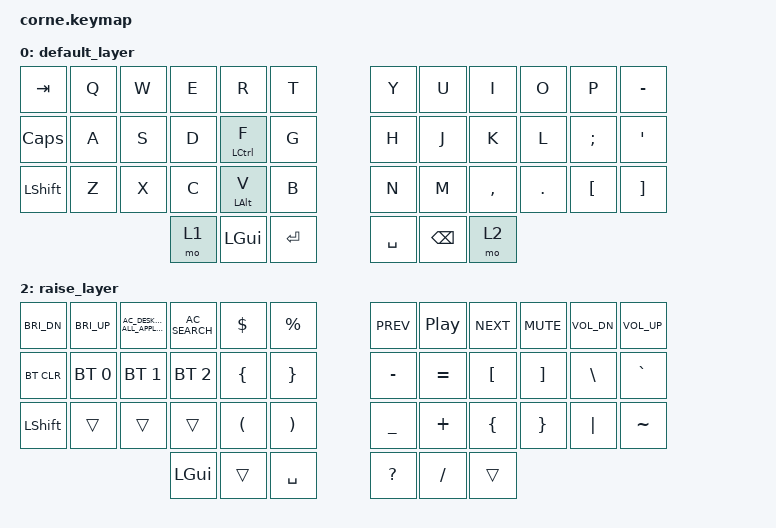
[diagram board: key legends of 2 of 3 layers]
/*
 * Copyright (c) 2020 The ZMK Contributors
 *
 * SPDX-License-Identifier: MIT
 */

#include <behaviors.dtsi>
#include <dt-bindings/zmk/keys.h>
#include <dt-bindings/zmk/bt.h>

&mt {
    flavor = "balanced";
    tapping-term-ms = <300>;
};

/ {
        keymap {
                compatible = "zmk,keymap";

                default_layer {
// -----------------------------------------------------------------------------------------
// |  TAB |  Q  |  W  |  E  |  R  |  T  |   |  Y  |  U   |  I  |  O  |  P  |  -   |
// | CAPS |  A  |  S  |  D  |F,CMD|  G  |   |  H  |  J   |  K  |  L  |  ;  |  '   |
// | SHFT |  Z  |  X  |  C  |V,ALT|  B  |   |  N  |  M   |  ,  |  .  |  [  |  ]   |
//                    | LWR | GUI | ENT |   | SPC | BKSP | RSE |
                        bindings = <
   &kp TAB   &kp Q &kp W &kp E &kp R &kp T        &kp Y &kp U  &kp I     &kp O   &kp P    &kp MINUS
   &kp CAPS &kp A &kp S &kp D &mt LCTRL F &kp G   &kp H &kp J  &kp K     &kp L   &kp SEMI &kp SQT
   &kp LSHFT &kp Z &kp X &kp C &mt LALT V &kp B        &kp N &kp M  &kp COMMA &kp DOT &kp LBKT  &kp RBKT
                  &mo 1 &kp LGUI &kp RET        &kp SPACE &kp BSPC &mo 2
                        >;
                };
                lower_layer {
// -----------------------------------------------------------------------------------------
// |  ESC |  !  |  @  |  #  |  $  |  %    |   |  1  |  2  |  3  |  +  |  -  |   =  |
// | BTPRV|  ^  |  &  |  *  |PG_UP| BTNXT |   |  4  |  5  |  6  |  *  |  UP |   :  |
// |      |  `  | END |HOME |PG_DN|SCRNSHT|   |  7  |  8  |  9  | LFT | DWN |  RGT |
//                    |     | GUI |       |   | ALT |  0  |     |
                        bindings = <
   &kp ESC  &kp EXCL &kp AT &kp NON_US_HASH &kp DLLR &kp PRCNT                         &kp N1   &kp N2   &kp N3  &kp KP_PLUS  &kp KP_MINUS &kp KP_EQUAL
   &bt BT_PRV &kp CARET &kp AMPS  &kp KP_MULTIPLY &bt &kp PG_UP &bt BT_NXT   &kp N4  &kp N5  &kp N6  &kp KP_MULTIPLY &kp UP &kp KP_DIVIDE
   &trans  &kp GRAVE  &kp END  &kp HOME  &kp PG_DN  &kp LS(LC(LG(N4)))     &kp N7  &kp N8  &kp N9  &kp LEFT &kp DOWN &kp RIGHT
                                            &trans     &kp LGUI  &trans   &kp RALT  &kp N0   &trans
                        >;
                };

                raise_layer {
// -----------------------------------------------------------------------------------------
// | BRI_DN|BRI_UP| APP | SRCH|  $  |  %  |   | PREV| PLAY|NEXT | MUTE|VOL_DN|VOL_UP |
// | BTCLR | BT1  | BT2 | BT3 |  {  |  }  |   |  -  |  =  |  [  |  ]  |  \   |  `    |
// | SHFT  |      |     |     |  (  |  )  |   |  _  |  +  |  {  |  }  | "|"  |  ~    |
//                      | GUI |     | SPC |   |  ?  |  /  |     |
                        bindings = <
   &kp C_BRI_DN  &kp C_BRI_UP &kp C_AC_DESKTOP_SHOW_ALL_APPLICATIONS &kp C_AC_SEARCH &kp DLLR &kp PRCNT     &kp C_PREV &kp C_PP  &kp C_NEXT &kp C_MUTE &kp C_VOL_DN &kp C_VOL_UP
   &bt BT_CLR &bt BT_SEL 0 &bt BT_SEL 1 &bt BT_SEL 2  &kp LBRC  &kp RBRC       &kp MINUS &kp EQUAL &kp LBKT  &kp RBKT &kp BSLH &kp GRAVE
   &kp LSHFT &trans   &trans &trans   &kp LPAR &kp RPAR             &kp UNDER &kp PLUS  &kp LBRC   &kp RBRC &kp PIPE &kp TILDE
                             &kp LGUI &trans   &kp SPACE           &kp QMARK   &kp SLASH    &trans
                        >;
                };
        };
};
